# N572F065_v3 register map
File version: 1.0
Registers are 32-bit, read-write, reset 0x0 unless marked. A register's access mark holds for its fields unless they carry their own. Offsets are from the block's base; [hi:lo] are bit positions; {n}, {i} and the like mark numbered series.

## APU — APU Register Map
Base 0x400C0000
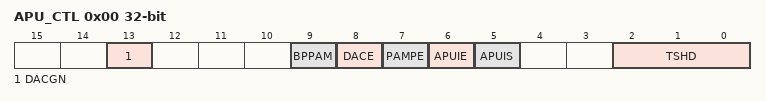
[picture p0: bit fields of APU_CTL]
0x00 APU_CTL — APU Control Register
  [13] DACGN — DAC Output Current Control. This bit is effective only when BPPAM is "1".
    0=3mA; 1=5mA
  [9] BPPAM — Bypass Power Amplifier, DAC Output To Pin. Note: User must set BPPAM to "0" to use SPK+ and SPK- as the power amplifier outputs.
    0=SPK+ and SPK- are power amplifier outputs; 1=No output at SPK-. This setting is for testing only and prohibited for normal operation
  [8] DACE — DAC Enable
    0=Disable DAC function; 1=Enable DAC function
  [7] PAMPE — Power Amplifier Enable
    0=Disable PA function; 1=Enable PA function
  [6] APUIE — APU Interrupt Enable
    0=Disable the APU threshold interrupt; 1=Enable the APU threshold interrupt
  [5] APUIS — APU Interrupt Status. This flag is set by hardware when APU threshold is met. Software can clear this bit by writing a zero to it.
    0=APU threshold interrupt does not occur; 1=APU threshold interrupt occur
  [2:0] TSHD — APU Interrupt Threshold
    {v}=Buffer {v} is read out by APU (v=0..7)
0x04 APU_VM — APU Volume Control Register
  [2:0] VOLUM — APU Volume Adjustment
    0=0 dB; 1=-3 dB; 2=-6 dB; 3=-9 dB; 4=-12 dB; 5=-15 dB; 6=-18 dB
0x0C APU_CH1DAT0 — APU Channel 1 Data Buffer Register
  [12:0] PCM1 — PCM Data Of Channel 1. This field contains 13 bits PCM data that is one of the mixer input. The data format of PCM is 2'complement.
{0x10+4i} APU_CH0DAT{i} (i=0..7) — APU Channel 0 Data Buffer Register 0
  [12:0] PCM — PCM Data Of Channel 0. This field contains 13 bits PCM data that is one of the mixer input. The data format of PCM is 2'complement.

## CFG — CONFIGURE Register Map
Base 0x00300000
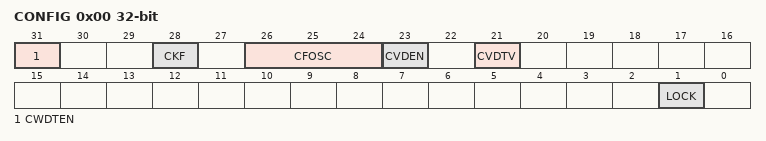
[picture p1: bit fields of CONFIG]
0x00 CONFIG — User Configuration Memory
  [31] CWDTEN — Watchdog Enable
    0=Watchdog is disabled after power on; 1=Watchdog is enabled after power on
  [28] CKF — Clock Filter Enable
    0=Disable clock filter; 1=Enable clock filter
  [26:24] CFOSC — Power-on Clock Source Selection
  [23] CVDEN — Voltage Detector Enable
    0=Enable Voltage Detector after power on; 1=Disable Voltage Detector after power on
  [21] CVDTV — Voltage Detector Threshold Voltage Selection
  [1] LOCK — Security Lock. When flash data is locked,(1) only device ID, CONFIG can be read by Writer and ICP thru serial debug interface. Other data are locked as 0xFFFFFFFF.(2) ISP can read data anywhere regardless of LOCK bit value. (3) SWD interface cannot access internal RAM and Flash
    0=Flash data are locked; 1=Flash data are not locked

## FMC — FMC Register Map
Base 0x5000C000
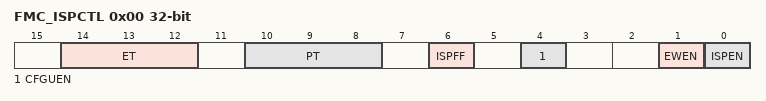
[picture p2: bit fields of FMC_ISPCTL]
0x00 FMC_ISPCTL — ISP Control Register
  [14:12] ET — Flash Page Erase Time
    0=20 ms (default); 1=25 ms; 2=30 ms; 3=35 ms; 4=3 ms; 5=5 ms; 6=10 ms; 7=15 ms
  [10:8] PT — Flash Program Time
    0=40 (s (default); 1=45 (s; 2=50 (s; 3=55 (s; 4=20 (s; 5=25 (s; 6=30 (s; 7=35 (s
  [6] ISPFF — ISP Fail Flag. This bit is set by hardware when a triggered ISP meets any of the following conditions: MCU writes (or erase) to Flash when EWEN is "0". Destination address is illegal, such as over an available range. . Write 1 to clear.
  [4] CFGUEN — CONFIG Update Enable. When enabled, ISP functions can access the CONFIG address space and modify device configuration area.
    0=Disable; 1=Enable
  [1] EWEN — Enable Erase/Write Of ISP Function
    0=Disable erase/write; 1=Enable erase/write
  [0] ISPEN — ISP Enable
    0=Disable ISP function; 1=Enable ISP function
0x04 FMC_ISPADDR — ISP Address Register
  [31:0] ISPADDR — ISP Address Register. This is the memory address register that a subsequent ISP command will access. ISP operation are carried out on 32-bit word only, consequently ISPADDR [1:0] must be 00b for correct ISP operation. N572F064 equips with an 16Kx32 bits embedded flash.
0x08 FMC_ISPDAT — ISP Data Register
  [31:0] ISPDAT — ISP Data Register. Write data to this register before an ISP program operation. Read data from this register after an ISP read operation
0x0C FMC_ISPCMD — ISP Command Register
  [5:0] CMD — ISP Command. Operation Mode : CMD -------------------- ------- Standby : 0x3X. Read CID : 0x0B. Read DID : 0x0C. Flash Page Erase : 0x22. Flash Program : 0x21. Flash Read : 0x00
0x10 FMC_ISPTRG — ISP Trigger Control Register
  [0] ISPGO — ISP Start Trigger. Write 1 to start ISP operation. This bit will be cleared to 0 by hardware automatically when ISP operation is finished.
    0=ISP operation is finished; 1=ISP is ongoing
0x18 FMC_FAT — Flash Access Time Control Register
